# MCXC444 register map
Vendor: NXP Semiconductors; Series: MCX; File version: 1.6
CPU: CM0PLUS r0p0, little endian, no MPU, no FPU, VTOR, 2 interrupt priority bits
Registers are 32-bit, read-write, reset 0x0 unless marked. A register's access mark holds for its fields unless they carry their own. Offsets are from the block's base; [hi:lo] are bit positions.

## UART2 — Serial Communication Interface
Base 0x4006C000; register names take the prefix UART2_
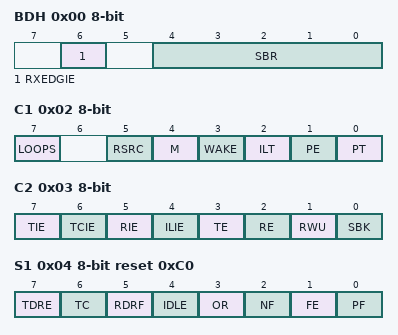
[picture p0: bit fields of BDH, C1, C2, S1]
0x00 BDH 8-bit — UART Baud Rate Registers: High
  [6] RXEDGIE — RxD Input Active Edge Interrupt Enable
    0=b0 (Hardware interrupts from RXEDGIF disabled using polling.); 1=b1 (RXEDGIF interrupt request enabled.)
  [4:0] SBR — UART Baud Rate Bits
0x01 BDL 8-bit reset 0x4 — UART Baud Rate Registers: Low
  [7:0] SBR — UART Baud Rate Bits
0x02 C1 8-bit — UART Control Register 1
  [7] LOOPS — Loop Mode Select
    0=b0 (Normal operation.); 1=b1 (Loop mode where transmitter output is internally connected to receiver input. The receiver input is determined by RSRC.)
  [5] RSRC — Receiver Source Select
    0=b0 (Selects internal loop back mode. The receiver input is internally connected to transmitter output.); 1=b1 (Single wire UART mode where the receiver input is connected to the transmit pin input signal.)
  [4] M — 9-bit or 8-bit Mode Select
    0=b0 (Normal-start + 8 data bits (MSB/LSB first as determined by MSBF) + stop.); 1=b1 (Use-start + 9 data bits (MSB/LSB first as determined by MSBF) + stop.)
  [3] WAKE — Receiver Wakeup Method Select
    0=b0 (Idle line wakeup.); 1=b1 (Address mark wakeup.)
  [2] ILT — Idle Line Type Select
    0=b0 (Idle character bit count starts after start bit.); 1=b1 (Idle character bit count starts after stop bit.)
  [1] PE — Parity Enable
    0=b0 (Parity function disabled.); 1=b1 (Parity function enabled.)
  [0] PT — Parity Type
    0=b0 (Even parity.); 1=b1 (Odd parity.)
0x03 C2 8-bit — UART Control Register 2
  [7] TIE — Transmitter Interrupt or DMA Transfer Enable.
    0=b0 (TDRE interrupt and DMA transfer requests disabled.); 1=b1 (TDRE interrupt or DMA transfer requests enabled.)
  [6] TCIE — Transmission Complete Interrupt Enable
    0=b0 (TC interrupt requests disabled.); 1=b1 (TC interrupt requests enabled.)
  [5] RIE — Receiver Full Interrupt or DMA Transfer Enable
    0=b0 (RDRF interrupt and DMA transfer requests disabled.); 1=b1 (RDRF interrupt or DMA transfer requests enabled.)
  [4] ILIE — Idle Line Interrupt Enable
    0=b0 (IDLE interrupt requests disabled.); 1=b1 (IDLE interrupt requests enabled.)
  [3] TE — Transmitter Enable
    0=b0 (Transmitter off.); 1=b1 (Transmitter on.)
  [2] RE — Receiver Enable
    0=b0 (Receiver off.); 1=b1 (Receiver on.)
  [1] RWU — Receiver Wakeup Control
    0=b0 (Normal operation.); 1=b1 (RWU enables the wakeup function and inhibits further receiver interrupt requests. Normally, hardware wakes the receiver by automatically clearing RWU.)
  [0] SBK — Send Break
    0=b0 (Normal transmitter operation.); 1=b1 (Queue break characters to be sent.)
0x04 S1 8-bit ro reset 0xC0 — UART Status Register 1
  [7] TDRE — Transmit Data Register Empty Flag
    0=b0 (The amount of data in the transmit buffer is greater than the value indicated by TWFIFO[TXWATER].); 1=b1 (The amount of data in the transmit buffer is less than or equal to the value indicated by TWFIFO[TXWATER] at some point in time since the flag has been cleared.)
  [6] TC — Transmit Complete Flag
    0=b0 (Transmitter active (sending data, a preamble, or a break).); 1=b1 (Transmitter idle (transmission activity complete).)
  [5] RDRF — Receive Data Register Full Flag
    0=b0 (The number of datawords in the receive buffer is less than the number indicated by RXWATER.); 1=b1 (The number of datawords in the receive buffer is equal to or greater than the number indicated by RXWATER at some point in time since this flag was last cleared.)
  [4] IDLE — Idle Line Flag
    0=b0 (Receiver input is either active now or has never become active since the IDLE flag was last cleared.); 1=b1 (Receiver input has become idle or the flag has not been cleared since it last asserted.)
  [3] OR — Receiver Overrun Flag
    0=b0 (No overrun has occurred since the last time the flag was cleared.); 1=b1 (Overrun has occurred or the overrun flag has not been cleared since the last overrun occured.)
  [2] NF — Noise Flag
    0=b0 (No noise detected since the last time this flag was cleared. If the receive buffer has a depth greater than 1 then there may be data in the receiver buffer that was received with noise.); 1=b1 (At least one dataword was received with noise detected since the last time the flag was cleared.)
  [1] FE — Framing Error Flag
    0=b0 (No framing error detected.); 1=b1 (Framing error.)
  [0] PF — Parity Error Flag
    0=b0 (No parity error detected since the last time this flag was cleared. If the receive buffer has a depth greater than 1, then there may be data in the receive buffer what was received with a parity error.); 1=b1 (At least one dataword was received with a parity error since the last time this flag was cleared.)
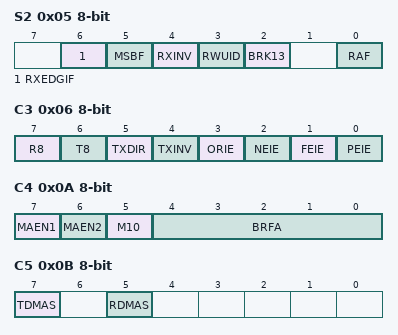
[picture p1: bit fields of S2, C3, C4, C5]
0x05 S2 8-bit — UART Status Register 2
  [6] RXEDGIF — RxD Pin Active Edge Interrupt Flag
    0=b0 (No active edge on the receive pin has occurred.); 1=b1 (An active edge on the receive pin has occurred.)
  [5] MSBF — Most Significant Bit First
    0=b0 (LSB (bit0) is the first bit that is transmitted following the start bit. Further, the first bit received after the start bit is identified as bit0.); 1=b1 (MSB (bit8, bit7 or bit6) is the first bit that is transmitted following the start bit, depending on the setting of C1[M] and C1[PE]. Further, the first bit received after the start bit is identified as bit8, bit7, or bit6, depending on the setting of C1[M] and C1[PE].)
  [4] RXINV — Receive Data Inversion
    0=b0 (Receive data is not inverted.); 1=b1 (Receive data is inverted.)
  [3] RWUID — Receive Wakeup Idle Detect
    0=b0 (S1[IDLE] is not set upon detection of an idle character.); 1=b1 (S1[IDLE] is set upon detection of an idle character.)
  [2] BRK13 — Break Transmit Character Length
    0=b0 (Break character is 10, 11, or 12 bits long.); 1=b1 (Break character is 13 or 14 bits long.)
  [0] RAF ro — Receiver Active Flag
    0=b0 (UART receiver idle/inactive waiting for a start bit.); 1=b1 (UART receiver active, RxD input not idle.)
0x06 C3 8-bit — UART Control Register 3
  [7] R8 ro — Received Bit 8
  [6] T8 — Transmit Bit 8
  [5] TXDIR — Transmitter Pin Data Direction in Single-Wire mode
    0=b0 (TXD pin is an input in single wire mode.); 1=b1 (TXD pin is an output in single wire mode.)
  [4] TXINV — Transmit Data Inversion.
    0=b0 (Transmit data is not inverted.); 1=b1 (Transmit data is inverted.)
  [3] ORIE — Overrun Error Interrupt Enable
    0=b0 (OR interrupts are disabled.); 1=b1 (OR interrupt requests are enabled.)
  [2] NEIE — Noise Error Interrupt Enable
    0=b0 (NF interrupt requests are disabled.); 1=b1 (NF interrupt requests are enabled.)
  [1] FEIE — Framing Error Interrupt Enable
    0=b0 (FE interrupt requests are disabled.); 1=b1 (FE interrupt requests are enabled.)
  [0] PEIE — Parity Error Interrupt Enable
    0=b0 (PF interrupt requests are disabled.); 1=b1 (PF interrupt requests are enabled.)
0x07 D 8-bit — UART Data Register
  [7:0] RT — Reads return the contents of the read-only receive data register and writes go to the write-only transmit data register
0x08 MA1 8-bit — UART Match Address Registers 1
  [7:0] MA — Match Address
0x09 MA2 8-bit — UART Match Address Registers 2
  [7:0] MA — Match Address
0x0A C4 8-bit — UART Control Register 4
  [7] MAEN1 — Match Address Mode Enable 1
    0=b0 (All data received is transferred to the data buffer if MAEN2 is cleared.); 1=b1 (All data received with the most significant bit cleared, is discarded. All data received with the most significant bit set, is compared with contents of MA1 register. If no match occurs, the data is discarded. If match occurs, data is transferred to the data buffer. This field must be cleared when C7816[ISO7816E] is set/enabled.)
  [6] MAEN2 — Match Address Mode Enable 2
    0=b0 (All data received is transferred to the data buffer if MAEN1 is cleared.); 1=b1 (All data received with the most significant bit cleared, is discarded. All data received with the most significant bit set, is compared with contents of MA2 register. If no match occurs, the data is discarded. If a match occurs, data is transferred to the data buffer. This field must be cleared when C7816[ISO7816E] is set/enabled.)
  [5] M10 — 10-bit Mode select
    0=b0 (The parity bit is the ninth bit in the serial transmission.); 1=b1 (The parity bit is the tenth bit in the serial transmission.)
  [4:0] BRFA — Baud Rate Fine Adjust
0x0B C5 8-bit — UART Control Register 5
  [7] TDMAS — Transmitter DMA Select
    0=b0 (If C2[TIE] is set and the S1[TDRE] flag is set, the TDRE interrupt request signal is asserted to request interrupt service.); 1=b1 (If C2[TIE] is set and the S1[TDRE] flag is set, the TDRE DMA request signal is asserted to request a DMA transfer.)
  [5] RDMAS — Receiver Full DMA Select
    0=b0 (If C2[RIE] and S1[RDRF] are set, the RDFR interrupt request signal is asserted to request an interrupt service.); 1=b1 (If C2[RIE] and S1[RDRF] are set, the RDRF DMA request signal is asserted to request a DMA transfer.)
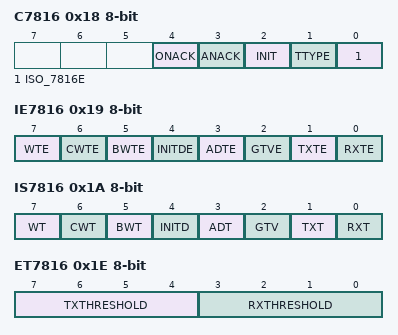
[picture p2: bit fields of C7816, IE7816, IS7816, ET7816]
0x18 C7816 8-bit — UART 7816 Control Register
  [4] ONACK — Generate NACK on Overflow
    0=b0 (The received data does not generate a NACK when the receipt of the data results in an overflow event.); 1=b1 (If the receiver buffer overflows, a NACK is automatically sent on a received character.)
  [3] ANACK — Generate NACK on Error
    0=b0 (No NACK is automatically generated.); 1=b1 (A NACK is automatically generated if a parity error is detected or if an invalid initial character is detected.)
  [2] INIT — Detect Initial Character
    0=b0 (Normal operating mode. Receiver does not seek to identify initial character.); 1=b1 (Receiver searches for initial character.)
  [1] TTYPE — Transfer Type
    0=b0 (T = 0 per the ISO-7816 specification.); 1=b1 (T = 1 per the ISO-7816 specification.)
  [0] ISO_7816E — ISO-7816 Functionality Enabled
    0=b0 (ISO-7816 functionality is turned off/not enabled.); 1=b1 (ISO-7816 functionality is turned on/enabled.)
0x19 IE7816 8-bit — UART 7816 Interrupt Enable Register
  [7] WTE — Wait Timer Interrupt Enable
    0=b0 (The assertion of IS7816[WT] does not result in the generation of an interrupt.); 1=b1 (The assertion of IS7816[WT] results in the generation of an interrupt.)
  [6] CWTE — Character Wait Timer Interrupt Enable
    0=b0 (The assertion of IS7816[CWT] does not result in the generation of an interrupt.); 1=b1 (The assertion of IS7816[CWT] results in the generation of an interrupt.)
  [5] BWTE — Block Wait Timer Interrupt Enable
    0=b0 (The assertion of IS7816[BWT] does not result in the generation of an interrupt.); 1=b1 (The assertion of IS7816[BWT] results in the generation of an interrupt.)
  [4] INITDE — Initial Character Detected Interrupt Enable
    0=b0 (The assertion of IS7816[INITD] does not result in the generation of an interrupt.); 1=b1 (The assertion of IS7816[INITD] results in the generation of an interrupt.)
  [3] ADTE — ATR Duration Timer Interrupt Enable
    0=b0 (The assertion of IS7816[ADT] does not result in the generation of an interrupt.); 1=b1 (The assertion of IS7816[ADT] results in the generation of an interrupt.)
  [2] GTVE — Guard Timer Violated Interrupt Enable
    0=b0 (The assertion of IS7816[GTV] does not result in the generation of an interrupt.); 1=b1 (The assertion of IS7816[GTV] results in the generation of an interrupt.)
  [1] TXTE — Transmit Threshold Exceeded Interrupt Enable
    0=b0 (The assertion of IS7816[TXT] does not result in the generation of an interrupt.); 1=b1 (The assertion of IS7816[TXT] results in the generation of an interrupt.)
  [0] RXTE — Receive Threshold Exceeded Interrupt Enable
    0=b0 (The assertion of IS7816[RXT] does not result in the generation of an interrupt.); 1=b1 (The assertion of IS7816[RXT] results in the generation of an interrupt.)
0x1A IS7816 8-bit — UART 7816 Interrupt Status Register
  [7] WT — Wait Timer Interrupt
    0=b0 (Wait time (WT) has not been violated.); 1=b1 (Wait time (WT) has been violated.)
  [6] CWT — Character Wait Timer Interrupt
    0=b0 (Character wait time (CWT) has not been violated.); 1=b1 (Character wait time (CWT) has been violated.)
  [5] BWT — Block Wait Timer Interrupt
    0=b0 (Block wait time (BWT) has not been violated.); 1=b1 (Block wait time (BWT) has been violated.)
  [4] INITD — Initial Character Detected Interrupt
    0=b0 (A valid initial character has not been received.); 1=b1 (A valid initial character has been received.)
  [3] ADT — ATR Duration Time Interrupt
    0=b0 (ATR Duration time (ADT) has not been violated.); 1=b1 (ATR Duration time (ADT) has been violated.)
  [2] GTV — Guard Timer Violated Interrupt
    0=b0 (A guard time (GT, CGT, or BGT) has not been violated.); 1=b1 (A guard time (GT, CGT, or BGT) has been violated.)
  [1] TXT — Transmit Threshold Exceeded Interrupt
    0=b0 (The number of retries and corresponding NACKS does not exceed the value in ET7816[TXTHRESHOLD].); 1=b1 (The number of retries and corresponding NACKS exceeds the value in ET7816[TXTHRESHOLD].)
  [0] RXT — Receive Threshold Exceeded Interrupt
    0=b0 (The number of consecutive NACKS generated as a result of parity errors and buffer overruns is less than or equal to the value in ET7816[RXTHRESHOLD].); 1=b1 (The number of consecutive NACKS generated as a result of parity errors and buffer overruns is greater than the value in ET7816[RXTHRESHOLD].)
0x1B WP7816 8-bit — UART 7816 Wait Parameter Register
  [7:0] WTX — Wait Time Multiplier (C7816[TTYPE] = 1)
0x1C WN7816 8-bit — UART 7816 Wait N Register
  [7:0] GTN — Guard Band N
0x1D WF7816 8-bit reset 0x1 — UART 7816 Wait FD Register
  [7:0] GTFD — FD Multiplier
0x1E ET7816 8-bit — UART 7816 Error Threshold Register
  [7:4] TXTHRESHOLD — Transmit NACK Threshold
    0=b0000 (TXT asserts on the first NACK that is received.); 1=b0001 (TXT asserts on the second NACK that is received.)
  [3:0] RXTHRESHOLD — Receive NACK Threshold
0x1F TL7816 8-bit — UART 7816 Transmit Length Register
  [7:0] TLEN — Transmit Length
0x3A AP7816A_T0 8-bit — UART 7816 ATR Duration Timer Register A
  [7:0] ADTI_H — ATR Duration Time Integer High (C7816[TTYPE] = 0)
0x3B AP7816B_T0 8-bit — UART 7816 ATR Duration Timer Register B
  [7:0] ADTI_L — ATR Duration Time Integer Low (C7816[TTYPE] = 0)
0x3C WP7816A_T0 8-bit (UART2 view) — UART 7816 Wait Parameter Register A
  [7:0] WI_H — Wait Time Integer High (C7816[TTYPE] = 0)
0x3C WP7816A_T1 8-bit (UART2 view) — UART 7816 Wait Parameter Register A
  [7:0] BWI_H — Block Wait Time Integer High (C7816[TTYPE] = 1)
0x3D WP7816B_T0 8-bit reset 0x14 (UART2 view) — UART 7816 Wait Parameter Register B
  [7:0] WI_L — Wait Time Integer Low (C7816[TTYPE] = 0)
0x3D WP7816B_T1 8-bit reset 0x14 (UART2 view) — UART 7816 Wait Parameter Register B
  [7:0] BWI_L — Block Wait Time Integer Low (C7816[TTYPE] = 1)
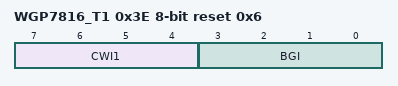
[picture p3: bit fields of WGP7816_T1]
0x3E WGP7816_T1 8-bit reset 0x6 — UART 7816 Wait and Guard Parameter Register
  [7:4] CWI1 — Character Wait Time Integer 1 (C7816[TTYPE] = 1)
  [3:0] BGI — Block Guard Time Integer (C7816[TTYPE] = 1)
0x3F WP7816C_T1 8-bit reset 0xB — UART 7816 Wait Parameter Register C
  [4:0] CWI2 — Character Wait Time Integer 2 (C7816[TTYPE] = 1)
